# nrf54l05_application register map
Vendor: Nordic Semiconductor; Series: nrf54l; File version: 1
CPU: CM33 r0p4, little endian, MPU, FPU, 3 interrupt priority bits, 270 interrupts, 4 SAU regions
Registers are 32-bit, read-write, reset 0x0 unless marked. A register's access mark holds for its fields unless they carry their own. Offsets are from the block's base; [hi:lo] are bit positions; lines under a group give offsets from that group; {n}, {i} and the like mark numbered series; 'fields as' and 'values as' point back to an identical list.

## GLOBAL_TAD_NS — Trace and debug control 0
Base 0x40053000
Same registers: GLOBAL_TAD_S 0x50053000
0x400 SYSPWRUPREQ — System power-up request
  [0] ACTIVE — Activate power-up request
    0=NotActive (Power-up request not active); 1=Active (Power-up request active)
0x404 DBGPWRUPREQ — Debug power-up request
  fields as SYSPWRUPREQ
0x500 ENABLE — Enable debug domain and aquire selected GPIOs
  [0] ENABLE
    0=DISABLED (Disable debug domain and release selected GPIOs); 1=ENABLED (Enable debug domain and aquire selected GPIOs)
0x518 TRACEPORTSPEED
  [1:0] TRACEPORTSPEED — Trace port speed is divided from CPU clock. The TRACECLK pin output will be divided again by two from the trace port clock.
    0=DIV1 (Trace port speed equals CPU clock); 1=DIV2 (Trace port speed equals CPU clock divided by 2); 2=DIV4 (Trace port speed equals CPU clock divided by 4); 3=DIV32 (Trace port speed equals CPU clock divided by 32)

## GLOBAL_EGU10_NS — Event generator unit 0
Base 0x40087000
Same registers: GLOBAL_EGU20_NS 0x400C9000, GLOBAL_EGU10_S 0x50087000, GLOBAL_EGU20_S 0x500C9000
{0x0+4i} TASKS_TRIGGER[{i}] (i=0..15) wo — Description collection: Trigger n for triggering the corresponding TRIGGERED[n] event
  [0] TASKS_TRIGGER — Trigger n for triggering the corresponding TRIGGERED[n] event
    1=Trigger task
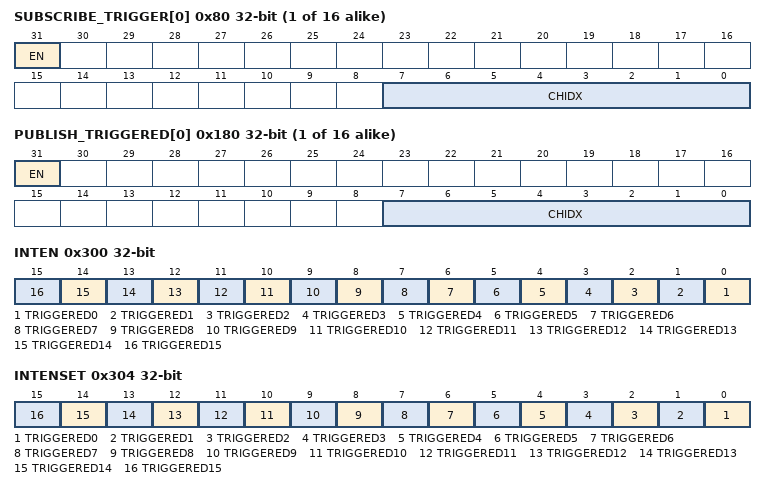
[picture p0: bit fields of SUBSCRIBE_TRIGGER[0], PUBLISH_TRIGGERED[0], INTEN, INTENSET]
{0x80+4i} SUBSCRIBE_TRIGGER[{i}] (i=0..15) — Description collection: Subscribe configuration for task TRIGGER[n]
  [31] EN
    0=Disabled (Disable subscription); 1=Enabled (Enable subscription)
  [7:0] CHIDX — DPPI channel that task TRIGGER[n] will subscribe to
{0x100+4i} EVENTS_TRIGGERED[{i}] (i=0..15) — Description collection: Event number n generated by triggering the corresponding TRIGGER[n] task
  [0] EVENTS_TRIGGERED — Event number n generated by triggering the corresponding TRIGGER[n] task
    0=NotGenerated (Event not generated); 1=Generated (Event generated)
{0x180+4i} PUBLISH_TRIGGERED[{i}] (i=0..15) — Description collection: Publish configuration for event TRIGGERED[n]
  [31] EN
    0=Disabled (Disable publishing); 1=Enabled (Enable publishing)
  [7:0] CHIDX — DPPI channel that event TRIGGERED[n] will publish to
0x300 INTEN — Enable or disable interrupt
  [all] fields
    0=Disabled; 1=Enabled
  [n] TRIGGERED{n} (n=0..15) — Enable or disable interrupt for event TRIGGERED[{n}]
0x304 INTENSET — Enable interrupt
  [all] fields
    on read: 0=Disabled (Read: Disabled); 1=Enabled (Read: Enabled) | on write: 1=Set (Enable)
  [n] TRIGGERED{n} write-1-sets (n=0..15) — Write '1' to enable interrupt for event TRIGGERED[{n}]
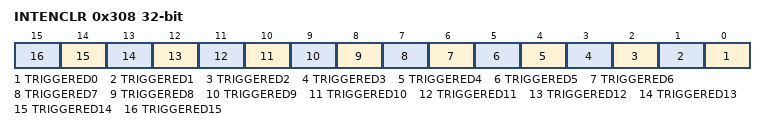
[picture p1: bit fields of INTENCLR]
0x308 INTENCLR — Disable interrupt
  [all] fields
    on read: 0=Disabled (Read: Disabled); 1=Enabled (Read: Enabled) | on write: 1=Clear (Disable)
  [n] TRIGGERED{n} write-1-clears (n=0..15) — Write '1' to disable interrupt for event TRIGGERED[{n}]

## GLOBAL_MEMCONF_NS — Memory configuration 0
Base 0x400CF000
Same registers: GLOBAL_MEMCONF_S 0x500CF000
{0x500+0x10*i} POWER[{i}] (i=0..1) group — Unspecified
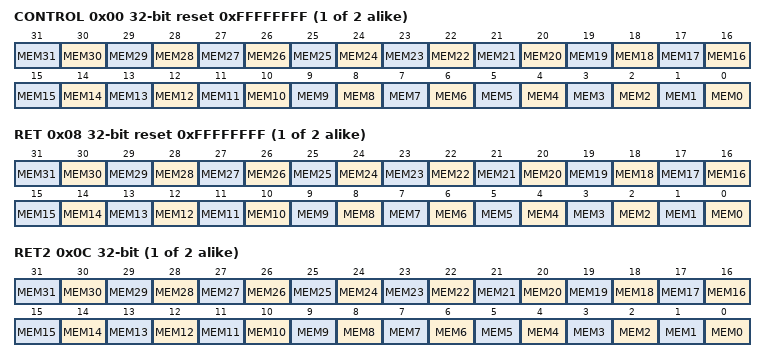
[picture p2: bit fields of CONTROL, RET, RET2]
  0x00 CONTROL reset 0xFFFFFFFF — Description cluster: Control memory block power.
    [all] fields
      0=Off (Power down); 1=On (Power up)
    [n] MEM{n} (n=0..31) — Keep the memory block MEM[{n}] on or off when in System ON mode.
  0x08 RET reset 0xFFFFFFFF — Description cluster: RAM retention for RAM [n].
    [all] fields
      0=Off (Retention off); 1=On (Retention on)
    [n] MEM{n} (n=0..31) — Keep the RAM block MEM[{n}] retained when in System OFF mode.
  0x0C RET2 — Description cluster: RAM retention for the second bank in the RAM block
    [all] fields
      0=Off (Retention off); 1=On (Retention on)
    [n] MEM{n} (n=0..31) — Keep the second bank in RAM block MEM[{n}] retained when in System OFF mode.

## Notices in the file
Copyright (c) 2010 - 2025, Nordic Semiconductor ASA All rights reserved.
SPDX-License-Identifier: BSD-3-Clause
Redistribution and use in source and binary forms, with or without
modification, are permitted provided that the following conditions are met:
1. Redistributions of source code must retain the above copyright notice, this
list of conditions and the following disclaimer.
2. Redistributions in binary form must reproduce the above copyright
notice, this list of conditions and the following disclaimer in the
documentation and/or other materials provided with the distribution.
3. Neither the name of Nordic Semiconductor ASA nor the names of its
contributors may be used to endorse or promote products derived from this
software without specific prior written permission.
THIS SOFTWARE IS PROVIDED BY THE COPYRIGHT HOLDERS AND CONTRIBUTORS "AS IS"
AND ANY EXPRESS OR IMPLIED WARRANTIES, INCLUDING, BUT NOT LIMITED TO, THE
IMPLIED WARRANTIES OF MERCHANTABILITY, AND FITNESS FOR A PARTICULAR PURPOSE
ARE DISCLAIMED. IN NO EVENT SHALL NORDIC SEMICONDUCTOR ASA OR CONTRIBUTORS BE
LIABLE FOR ANY DIRECT, INDIRECT, INCIDENTAL, SPECIAL, EXEMPLARY, OR
CONSEQUENTIAL DAMAGES (INCLUDING, BUT NOT LIMITED TO, PROCUREMENT OF
SUBSTITUTE GOODS OR SERVICES; LOSS OF USE, DATA, OR PROFITS; OR BUSINESS
INTERRUPTION) HOWEVER CAUSED AND ON ANY THEORY OF LIABILITY, WHETHER IN
CONTRACT, STRICT LIABILITY, OR TORT (INCLUDING NEGLIGENCE OR OTHERWISE)
ARISING IN ANY WAY OUT OF THE USE OF THIS SOFTWARE, EVEN IF ADVISED OF THE
POSSIBILITY OF SUCH DAMAGE.
